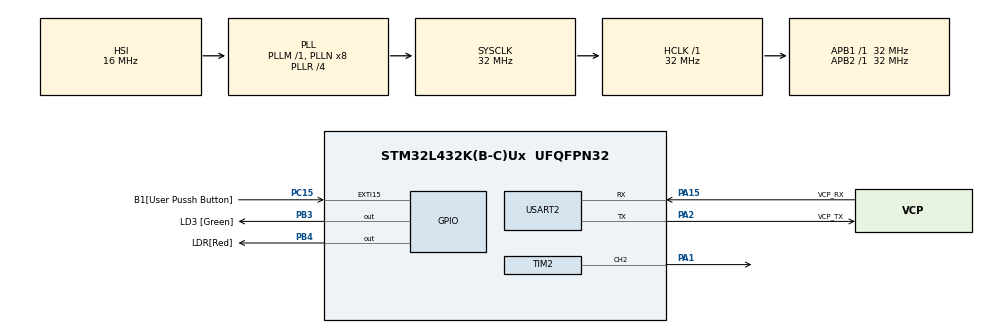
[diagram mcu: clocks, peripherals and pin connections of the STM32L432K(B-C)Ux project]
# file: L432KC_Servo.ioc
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Mcu.Family=STM32L4
Mcu.Name=STM32L432K(B-C)Ux
Mcu.Package=UFQFPN32
NVIC.PriorityGroup=NVIC_PRIORITYGROUP_4
NVIC.USART2_IRQn=true\:0\:0\:false\:false\:true\:true\:true\:true
PA1.Signal=S_TIM2_CH2
PA13\ (JTMS-SWDIO).GPIO_Label=SWDIO
PA13\ (JTMS-SWDIO).Mode=Serial_Wire
PA13\ (JTMS-SWDIO).Signal=SYS_JTMS-SWDIO
PA14\ (JTCK-SWCLK).GPIO_Label=SWCLK
PA14\ (JTCK-SWCLK).Mode=Serial_Wire
PA14\ (JTCK-SWCLK).Signal=SYS_JTCK-SWCLK
PA15\ (JTDI).GPIO_Label=VCP_RX
PA15\ (JTDI).Mode=Asynchronous
PA15\ (JTDI).Signal=USART2_RX
PA2.GPIO_Label=VCP_TX
PA2.Mode=Asynchronous
PA2.Signal=USART2_TX
PB3\ (JTDO-TRACESWO).GPIO_Label=LD3 [Green]
PB3\ (JTDO-TRACESWO).Signal=GPIO_Output
PB4\ (NJTRST).GPIO_Label=LDR[Red]
PB4\ (NJTRST).Signal=GPIO_Output
PC15-OSC32_OUT\ (PC15).GPIO_Label=B1[User Pussh Button]
PC15-OSC32_OUT\ (PC15).GPIO_PuPd=GPIO_PULLUP
PC15-OSC32_OUT\ (PC15).Signal=GPXTI15
ProjectManager.HeapSize=0x200
ProjectManager.StackSize=0x400
ProjectManager.TargetToolchain=STM32CubeIDE
RCC.ADCFreq_Value=64000000
RCC.AHBFreq_Value=32000000
RCC.APB1Freq_Value=32000000
RCC.APB1TimFreq_Value=32000000
RCC.APB2Freq_Value=32000000
RCC.APB2TimFreq_Value=32000000
RCC.CortexFreq_Value=32000000
RCC.HCLKFreq_Value=32000000
RCC.HSE_VALUE=8000000
RCC.HSI16_VALUE=16000000
RCC.HSI48_VALUE=48000000
RCC.HSI_VALUE=16000000
RCC.MSI_VALUE=4000000
RCC.PLLMUL=RCC_PLLMUL_4
RCC.PLLR=RCC_PLLR_DIV4
RCC.PLLSourceVirtual=RCC_PLLSOURCE_HSI
RCC.SYSCLKFreq_VALUE=32000000
RCC.SYSCLKSource=RCC_SYSCLKSOURCE_PLLCLK
RCC.USBFreq_Value=64000000
RCC.VCOOutputFreq_Value=128000000
SH.S_TIM2_CH2.0=TIM2_CH2,PWM Generation2 CH2
TIM2.Channel-PWM\ Generation2\ CH2=TIM_CHANNEL_2
TIM2.Period=19999
TIM2.Prescaler=31
TIM2.Pulse-PWM\ Generation2\ CH2=500
USART2.SwapParam=ADVFEATURE_SWAP_ENABLE
USART2.VirtualMode-Asynchronous=VM_ASYNC
board=NUCLEO-L432KC

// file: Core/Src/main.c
/* USER CODE BEGIN Header */
/**
 ******************************************************************************
 * @file           : main.c
 * @brief          : Main program body
 ******************************************************************************
 * @attention
 *
 * Copyright (c) 2025 STMicroelectronics.
 * All rights reserved.
 *
 * This software is licensed under terms that can be found in the LICENSE file
 * in the root directory of this software component.
 * If no LICENSE file comes with this software, it is provided AS-IS.
 *
 ******************************************************************************
 */
/* USER CODE END Header */
#include "main.h"
#include "tim.h"
#include "usart.h"
#include "gpio.h"

/* USER CODE BEGIN Includes */
#include "servo_control.h"
/* USER CODE END Includes */

void SystemClock_Config(void);

int main(void)
{

	/* MCU Configuration--------------------------------------------------------*/

	/* Reset of all peripherals, Initializes the Flash interface and the Systick. */
	HAL_Init();

	/* Configure the system clock */
	SystemClock_Config();

	/* Initialize all configured peripherals */
	MX_GPIO_Init();
	MX_USART2_UART_Init();
	MX_TIM2_Init();
	/* USER CODE BEGIN 2 */
	Servo_Init(&htim2, TIM_CHANNEL_2);
	HAL_UART_Transmit(&huart2, (uint8_t*)"\n\rVoulez vous tester la plage de rotation ? o/n.\r\n",50 , HAL_MAX_DELAY);
	HAL_UART_Receive(&huart2, MSG1, 1, HAL_MAX_DELAY);
	if(MSG1[0]=='o') Servo_Test_TimeSet(400, 3500);
	HAL_UART_Transmit(&huart2, (uint8_t*)"\n\rEntrez la valeur de rotation du servo entre 0 et 180 degrés.\r\n",64 , HAL_MAX_DELAY);
	HAL_UART_Receive_IT(&huart2, MSG1, 1);

	/* USER CODE END 2 */

	/* Infinite loop */
	while (1)
	{

	}
}

void SystemClock_Config(void)
{
	RCC_OscInitTypeDef RCC_OscInitStruct = {0};
	RCC_ClkInitTypeDef RCC_ClkInitStruct = {0};

	/** Configure the main internal regulator output voltage
	 */
	if (HAL_PWREx_ControlVoltageScaling(PWR_REGULATOR_VOLTAGE_SCALE1) != HAL_OK)
	{
		Error_Handler();
	}

	/** Initializes the RCC Oscillators according to the specified parameters
	 * in the RCC_OscInitTypeDef structure.
	 */
	RCC_OscInitStruct.OscillatorType = RCC_OSCILLATORTYPE_HSI;
	RCC_OscInitStruct.HSIState = RCC_HSI_ON;
	RCC_OscInitStruct.HSICalibrationValue = RCC_HSICALIBRATION_DEFAULT;
	RCC_OscInitStruct.PLL.PLLState = RCC_PLL_ON;
	RCC_OscInitStruct.PLL.PLLSource = RCC_PLLSOURCE_HSI;
	RCC_OscInitStruct.PLL.PLLM = 1;
	RCC_OscInitStruct.PLL.PLLN = 8;
	RCC_OscInitStruct.PLL.PLLP = RCC_PLLP_DIV7;
	RCC_OscInitStruct.PLL.PLLQ = RCC_PLLQ_DIV2;
	RCC_OscInitStruct.PLL.PLLR = RCC_PLLR_DIV4;
	if (HAL_RCC_OscConfig(&RCC_OscInitStruct) != HAL_OK)
	{
		Error_Handler();
	}

	/** Initializes the CPU, AHB and APB buses clocks
	 */
	RCC_ClkInitStruct.ClockType = RCC_CLOCKTYPE_HCLK|RCC_CLOCKTYPE_SYSCLK
			|RCC_CLOCKTYPE_PCLK1|RCC_CLOCKTYPE_PCLK2;
	RCC_ClkInitStruct.SYSCLKSource = RCC_SYSCLKSOURCE_PLLCLK;
	RCC_ClkInitStruct.AHBCLKDivider = RCC_SYSCLK_DIV1;
	RCC_ClkInitStruct.APB1CLKDivider = RCC_HCLK_DIV1;
	RCC_ClkInitStruct.APB2CLKDivider = RCC_HCLK_DIV1;

	if (HAL_RCC_ClockConfig(&RCC_ClkInitStruct, FLASH_LATENCY_1) != HAL_OK)
	{
		Error_Handler();
	}
}

void Error_Handler(void)
{
	__disable_irq();
	while (1)
	{
	}
}
